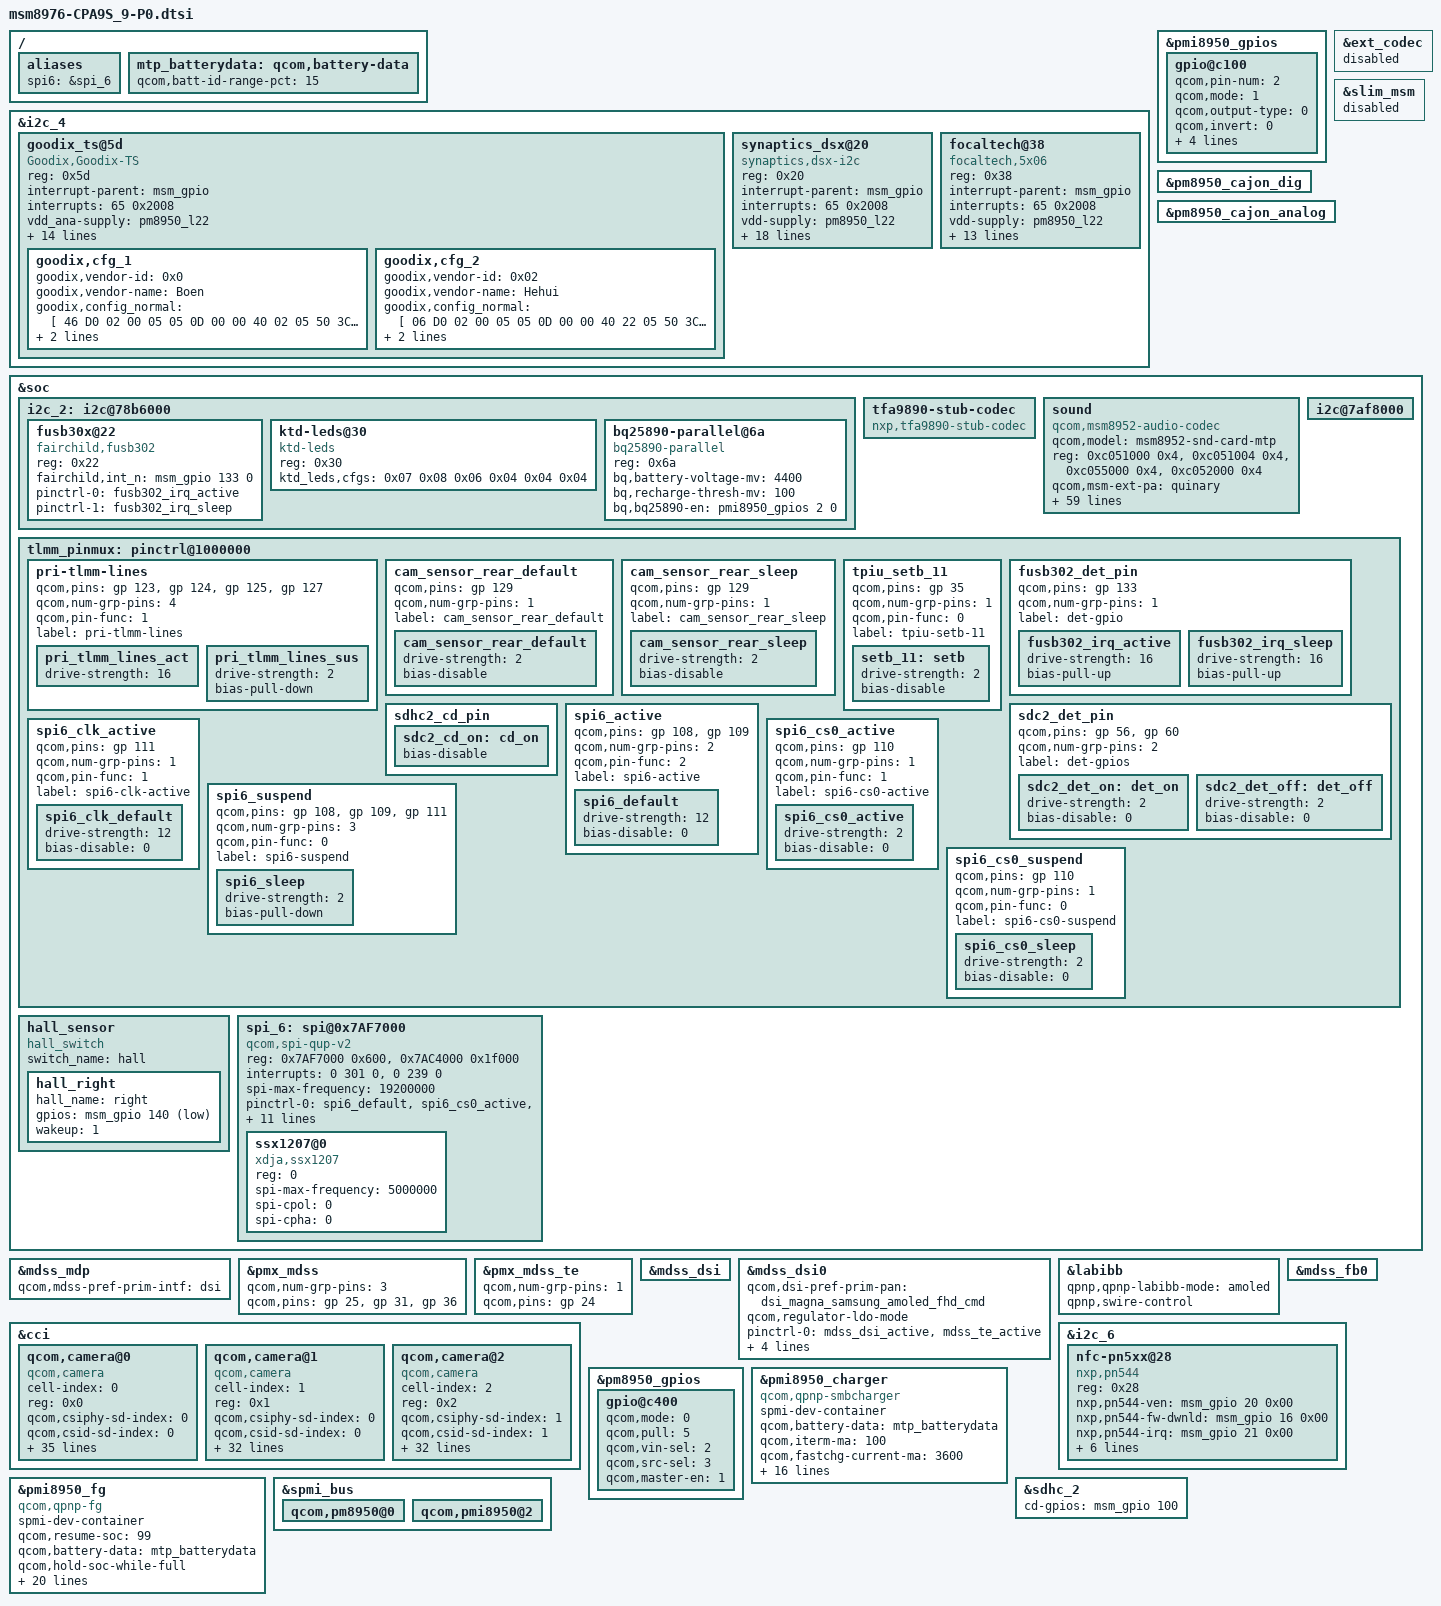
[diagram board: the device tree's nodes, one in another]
/* Copyright (c) 2014, The Linux Foundation. All rights reserved.
 *
 * This program is free software; you can redistribute it and/or modify
 * it under the terms of the GNU General Public License version 2 and
 * only version 2 as published by the Free Software Foundation.
 *
 * This program is distributed in the hope that it will be useful,
 * but WITHOUT ANY WARRANTY; without even the implied warranty of
 * MERCHANTABILITY or FITNESS FOR A PARTICULAR PURPOSE.  See the
 * GNU General Public License for more details.
 */

/* project CPA9S_9 */
/ {
	aliases {

		spi6 = &spi_6;
	};

};




&i2c_4 {
                goodix_ts@5d {
                        compatible = "Goodix,Goodix-TS";
                        reg = <0x5d>;
                        interrupt-parent = <&msm_gpio>;  /*<&tlmm>;*/
                        interrupts = <65 0x2008>;
                        vdd_ana-supply = <&pm8950_l22>;
                        vcc_i2c-supply = <&pm8950_l6>;
                        /* pins used by touchscreen */
                        pinctrl-names = "pmx_ts_active","pmx_ts_suspend";
                        pinctrl-0 = <&ts_int_active &ts_reset_active>;
                        pinctrl-1 = <&ts_int_suspend &ts_reset_suspend>;
                        goodix,vcc_i2c_supply_en = <&msm_gpio 35 0x0>;
                        goodix,irq-gpio = <&msm_gpio 65 0x2008>;	/*<&tlmm 65 0x2008> ;*/
                        goodix,reset-gpio = <&msm_gpio 64 0x0>; /*<&tlmm 64 0x0>;*/
                        goodix,irq_flags = <0x2>;
                        goodix,pixel = <720 1280>;
                        goodix,pwr_ctrl = <1>;
                        goodix,vdd = "vdd_ana";
                        goodix,vddio = "vcc_i2c";
                        goodix,ic_type = "GT1151";
                        goodix,charger_status_force_check = <0>;
                        goodix,cover = <0 0 540 300>; //x_min, y_min, x_max, y_max
                        /*touch config file*/

                        goodix,cfg_1 {
                                goodix,vendor-id = <0x0>;
                                goodix,vendor-name = "Boen";
                                goodix,config_normal = [
                                        46 D0 02 00 05 05 0D 00 00 40 02 05 50 3C 73 01 11
                                        00 00 00 41 8C A0 BE 08 00 00 00 00 00 00 00 00 31
                                        00 00 00 14 00 00 00 00 00 00 00 00 88 28 1C 52 54
                                        DF 07 38 6E 38 0D 33 24 00 04 32 78 C0 94 02 1E 0B
                                        03 C8 3D A6 49 8F 54 80 60 73 6C 6A 00 00 00 00 00
                                        00 00 00 00 00 00 00 00 19 19 00 00 00 00 00 0C 00
                                        00 00 00 00 88 00 00 00 00 00 FF 80 04 00 00 00 00
                                        00 00 00 00 00 00 00 00 00 00 00 00 00 00 00 00 00
                                        D0 07 41 1E 1F 1E 1D 1C 1B 1A 19 18 17 16 15 14 13
                                        0F 10 0E 0D 0C 0A 0B 09 08 06 07 04 05 02 03 FF FF
                                        FF 00 10 0F 0E 0D 0C 0B 0A 09 08 07 06 05 02 04 03
                                        01 FF 00 00 00 00 00 00 00 00 00 13 00 00 00 00 00
                                        00 00 00 00 00 00 00 00 00 00 00 00 00 00 00 00 00
                                        00 23 54 6E 31 14 3C 00 3A 20 03 00 D0 07 54 94 C7
                                        01
                                ];
                                goodix,config_glove = [
                                        46 D0 02 00 05 05 0D 00 00 40 02 05 46 32 73 01 11
                                        00 00 00 50 8C A0 BE 08 00 00 00 00 00 00 00 00 31
                                        00 00 00 14 00 00 00 00 00 00 00 00 88 28 1C 54 56
                                        DF 07 38 6E 38 0E 34 24 00 04 32 78 C0 94 02 1E 0B
                                        03 CD 3D A9 49 90 54 7F 60 72 6C 68 00 00 00 00 00
                                        00 00 00 00 00 00 00 00 19 19 00 00 00 00 00 0C 00
                                        00 00 00 00 88 00 00 00 00 00 FF 80 04 04 0A 0F 03
                                        1E B0 E1 E1 38 00 00 00 00 00 00 00 00 00 00 00 00
                                        D0 07 41 1E 1F 1E 1D 1C 1B 1A 19 18 17 16 15 14 13
                                        0F 10 0E 0D 0C 0A 0B 09 08 06 07 04 05 02 03 FF FF
                                        FF 00 10 0F 0E 0D 0C 0B 0A 09 08 07 06 05 02 04 03
                                        01 FF 00 00 00 00 00 00 00 00 00 13 00 00 00 00 00
                                        00 00 00 00 00 00 00 00 00 00 00 00 00 00 00 00 00
                                        00 23 54 6E 31 14 3C 00 3A 20 03 00 D0 07 54 94 C7
                                        01
                                ];
                        };
                         goodix,cfg_2 {
                                goodix,vendor-id = <0x02>;
                                goodix,vendor-name = "Hehui";
                                goodix,config_normal = [
					06 D0 02 00 05 05 0D 00 00 40 22 05 50 3C 73 01 11
					00 00 00 41 8C A0 BE 08 00 05 0A 00 00 00 11 00 31
					00 00 00 14 00 50 00 00 00 00 00 00 88 08 1C 49 00
					DF 07 38 6E 38 0D 33 24 11 04 32 78 C0 94 02 1E 0C
					03 C6 3D A5 49 8E 54 7F 60 73 6C 6B 00 00 00 00 00
					00 00 00 00 00 00 00 00 19 19 00 00 00 00 00 0C 00
					00 00 00 00 88 00 00 00 00 00 FF 80 04 00 00 00 00
					00 00 00 00 00 00 00 00 00 00 00 00 00 00 00 00 00
					C5 04 41 23 1F 1E 1D 1C 1B 1A 19 18 17 16 15 14 13
					12 10 0F 0E 0D 0C 0B 0A 09 08 07 06 05 04 03 FF FF
					FF 00 10 0F 0E 0D 0C 0B 0A 09 08 07 06 05 04 03 02
					01 FF 00 00 00 00 00 00 00 00 00 13 00 00 00 00 00
					00 00 00 00 00 00 00 00 00 00 00 00 00 00 00 00 00
					00 13 49 6D 31 14 3C 00 35 20 00 00 DF 07 49 14 7C
					01
                                ];
                                 goodix,config_glove = [
			                    08 D0 02 00 05 05 0D 00 00 40
			                    22 05 46 32 73 01 11 00 00 01
			                    3C 80 A0 CA 08 00 05 0A 00 00
			                    00 11 00 31 00 00 00 14 00 50
			                    00 00 00 00 00 00 88 28 1C 49
			                    4B DF 07 38 6D 38 0E 34 24 11
			                    04 32 78 C0 94 02 1E 14 04 B9
			                    3D 9E 49 8B 54 8B 60 77 6C 71
			                    00 00 00 00 00 00 00 00 00 00
			                    00 00 00 19 19 00 00 00 00 00
			                    0C 00 00 00 00 00 88 00 00 00
			                    00 00 FF 80 04 05 0A 0F 03 1E
			                    78 AA E1 38 00 00 00 00 00 00
			                    00 00 00 00 00 00 C5 04 3C 23
			                    03 05 04 07 06 09 08 0B 0A 0C
			                    0E 0D 0F 10 12 14 16 18 1A 1C
			                    1E 13 15 17 19 1B 1F 1D FF FF
			                    FF 00 01 03 02 05 04 06 07 09
			                    08 0B 10 0A 0F 0C 0E 0D FF 00
			                    00 00 00 00 00 00 00 00 13 00
			                    00 00 00 00 00 00 00 00 00 00
			                    00 00 00 00 00 00 00 00 00 00
			                    00 00 13 49 6D 31 14 3C 00 35
			                    20 03 00 D0 07 54 84 39 01
                                ];
                        };
                };

		/delete-node/ synaptics@20; 
             synaptics_dsx@20 {
			            compatible = "synaptics,dsx-i2c";
			            reg = <0x20>;
			            interrupt-parent = <&msm_gpio>;
			            interrupts = <65 0x2008>;
			            vdd-supply = <&pm8950_l22>;
			            vcc_i2c-supply = <&pm8950_l6>;
                                    synaptics,power-gpio = <&msm_gpio 35 0x0>;
                        	    synaptics,pwr-reg-name = "vdd";
                        	    synaptics,bus-reg-name = "vcc_i2c";
			            pinctrl-names = "pmx_ts_active","pmx_ts_suspend","pmx_ts_suspend";
			            pinctrl-0 = <&ts_int_active &ts_reset_active>;
			            pinctrl-1 = <&ts_int_suspend &ts_reset_suspend>;
                        	    pinctrl-2 = <&ts_release>;
			            synaptics,irq-gpio = <&msm_gpio 65 0x2008>;
			            synaptics,reset-gpio = <&msm_gpio 64 0x0>;
                        	    synaptics,irq-flags = <0x2008>;  
			            synaptics,power-delay-ms = <200>;
                                    synaptics,power-on-state = <1>;
			            synaptics,reset-delay-ms = <200>;
			            synaptics,reset-on-state = <0>;
			            synaptics,reset-active-ms = <20>;
                        	    synaptics,cap-button-codes = <580 102 158>;
                                    synaptics,x-flip = <1>;
                                    synaptics,y-flip = <1>;
		            };

    		focaltech@38{
			compatible = "focaltech,5x06";
			reg = <0x38>;
			interrupt-parent = <&msm_gpio>;
			interrupts = <65 0x2008>;
			vdd-supply = <&pm8950_l22>;
			vcc_i2c-supply = <&pm8950_l6>;
        	        focaltech,vcc_i2c_supply_en = <&msm_gpio 35 0x0>;
			focaltech,family-id = <0x06>;
			focaltech,reset-gpio = <&msm_gpio 64 0x0>;
			focaltech,irq-gpio = <&msm_gpio 65 0x2008>;
			focaltech,irq_flags = <0x2008>;
			focaltech,screen_x = <1080>;
			focaltech,screen_y = <1920>;
			focaltech,display-coords = <0 0 1080 1920>;
			focaltech,panel-coords = <0 0 1080 1920>;
			focaltech,button-map= <139 102 158>;
			focaltech,no-force-update;
			focaltech,i2c-pull-up;
		};

         /* shtsc tw */
/*	shtsc@18 {
		compatible = "sharp,shtsc_i2c";	
		reg = <0x18>;
		interrupt-parent = <&msm_gpio>;
		interrupts = <65 0x2008>;// high-level trigger. but hard coded in the source.
		vdd-supply = <&pm8950_l10>;
		vcc_i2c-supply = <&pm8950_l6>;
		sharp,vcc-i2c-supply-en = <&msm_gpio 34 0x00>;
		sharp,reset-gpio = <&msm_gpio 64 0x00>;
		sharp,irq-gpio = <&msm_gpio 65 0x2008>;
		pinctrl-names = "pmx_ts_active","pmx_ts_suspend";
		pinctrl-0 = <&ts_int_active &ts_reset_active>;
		pinctrl-1 = <&ts_int_suspend &ts_reset_suspend>;
		sharp,panel-coords = <0 0 1079 1919>; // depends on an LCD resolution (0 0 Xmax-1 Ymax-1)
		sharp,display-coords = <0 0 1079 1919>; // depends on an LCD resolution (0 0 Xmax-1 Ymax-1)
		sharp,i2c-pull-up;
		ts_touch_num_max = <10>;
		ts_pressure_max = <65535>;
		ts_flip_x = <0>;
		ts_flip_y = <0>;
		ts_swap_xy = <0>;

	};*/
};

&i2c_2 {
       /*KTD2026 Led*/
        ktd-leds@30 {
               compatible = "ktd-leds";
                reg = <0x30>;
                ktd_leds,cfgs = <
                    0x07 /*ktd_red_out Register */
                    0x08 /*ktd_green_out Register*/
                    0x06 /*ktd_blue_out Register */

                    0x04 /*ktd_red_current,15mA */
                    0x04 /*ktd_green_current,15mA */
                    0x04 /*ktd_blue_current,15mA */
                    >;
                };
                /*add end*/

	bq25890-parallel@6a {
                     compatible = "bq25890-parallel";
                     reg = <0x6a>;
                     bq,battery-voltage-mv = <4400>;
                     bq,recharge-thresh-mv = <100>;
                     bq,bq25890-en = <&pmi8950_gpios 2 0>;
                  };
};

&pmi8950_gpios {
                gpio@c100 {
                     qcom,pin-num = <2>;
                     qcom,mode = <1>;
                     qcom,output-type = <0>;
                     qcom,invert = <0>;
                     qcom,pull = <5>;
                     qcom,vin-sel = <0>;
                     qcom,src-sel = <2>;
                     qcom,master-en = <1>;
                     status = "okay";
               };
};

/**audio:disable external codec and enable internal codec,by lijiakan--start*/
&ext_codec {
        status = "disabled";
};
&slim_msm{
        status = "disabled";
};

&pm8950_cajon_dig {
        status = "ok";
};

&pm8950_cajon_analog {
        status = "ok";
};

&slim_msm {
	/delete-node/ tasha_codec;
};
&tlmm_pinmux {

                /delete-node/ cam_sensor_rear_default;
                cam_sensor_rear_default {
                        /* RESET, STANDBY */
                        qcom,pins = <&gp 129> ;
                        qcom,num-grp-pins = <1>;
                        label = "cam_sensor_rear_default";
                        /* active state */
                        cam_sensor_rear_default: cam_sensor_rear_default {
                                drive-strength = <2>; /* 2 MA */
                                bias-disable; /* No PULL */
                        };
                };

                /delete-node/ cam_sensor_rear_sleep;
                cam_sensor_rear_sleep {
                        /* RESET, STANDBY */
                        qcom,pins = <&gp 129>;
                        qcom,num-grp-pins = <1>;
                        label = "cam_sensor_rear_sleep";
                        /*suspended state */
                        cam_sensor_rear_sleep: cam_sensor_rear_sleep {
                                drive-strength = <2>; /* 2 MA */
                                bias-disable; /* No PULL */
                        };
                };

                tpiu_setb_11 {
                        qcom,pins = <&gp 35>;
                        qcom,num-grp-pins = <1>;
                        qcom,pin-func = <0>;
                        label = "tpiu-setb-11";
                        setb_11: setb {
                                drive-strength = <2>;
                                bias-disable;
                        };
                };

	fusb302_det_pin {
		qcom,pins = <&gp 133>;
		qcom,num-grp-pins = <1>;
		label = "det-gpio";
		fusb302_irq_active: fusb302_irq_active {
			drive-strength = <16>;
			bias-pull-up;
		};
		fusb302_irq_sleep: fusb302_irq_sleep {
			drive-strength = <16>;
			bias-pull-up;
		};
	};
};

/**audio:disable external codec and enable internal codec,by lijiakan  --end*/
/* fengdongjie add dts for audio start */
&soc {


	i2c_2: i2c@78b6000 { /* BLSP1 QUP2 */
		/* add usb type c for fusb302 */
		fusb30x@22 {
			compatible = "fairchild,fusb302";
                        reg = <0x22>;
                        fairchild,int_n = <&msm_gpio 133 0>;
                        pinctrl-names = "default", "sleep";
                        pinctrl-0 = <&fusb302_irq_active>;
                        pinctrl-1 = <&fusb302_irq_sleep>;
		};
	};

        /* add by wangyanzhong for tfa9890 */
        tfa9890-stub-codec {
                compatible = "nxp,tfa9890-stub-codec";
        };
        /* add end for tfa9890*/

	/delete-node/ sound-9335;
        sound {
                compatible = "qcom,msm8952-audio-codec";
                qcom,model = "msm8952-snd-card-mtp";
                reg = <0xc051000 0x4>,
                    <0xc051004 0x4>,
                    <0xc055000 0x4>,
                    <0xc052000 0x4>;
                reg-names = "csr_gp_io_mux_mic_ctl",
                        "csr_gp_io_mux_spkr_ctl",
                        "csr_gp_io_lpaif_pri_pcm_pri_mode_muxsel",
                        "csr_gp_io_mux_quin_ctl";

                /delete-property/ qcom,msm-ext-pa;
                qcom,msm-ext-pa = "quinary";
                qcom,msm-mclk-freq = <9600000>;
                qcom,msm-mbhc-hphl-swh = <1>;
                qcom,msm-mbhc-gnd-swh = <1>;
                qcom,msm-hs-micbias-type = "external";
                qcom,msm-micbias1-ext-cap;
                /* qcom,msm-spk-boost-ctl = <&msm_gpio 132 0>;*/
                qcom,audio-routing =
                        "RX_BIAS", "MCLK",
                        "SPK_RX_BIAS", "MCLK",
                        "INT_LDO_H", "MCLK",
                        "MIC BIAS External", "Handset Mic",
                        "MIC BIAS External2", "Headset Mic",
                        "MIC BIAS External", "Secondary Mic",
                        "AMIC1", "MIC BIAS External",
                        "AMIC2", "MIC BIAS External2",
                        "AMIC3", "MIC BIAS External";
                qcom,msm-gpios =
                        "pri_i2s",
                        /*"us_eu_gpio";*/
			"quin_i2s";
                qcom,pinctrl-names =
                        "all_off",
                        "pri_i2s_act",
                        /*"us_eu_gpio_act",
                         "pri_i2s_us_eu_gpio_act";*/
			"quin_i2s_act",
			"pri_i2s_quin_i2s_act";
                pinctrl-names =
                        "all_off",
                        "pri_i2s_act",
                        /*"us_eu_gpio_act",
                          "pri_i2s_us_eu_gpio_act";*/
			"quin_i2s_act",
			"pri_i2s_quin_i2s_act";
                /delete-property/ pinctrl-0;
                /delete-property/ pinctrl-1;
                /delete-property/ pinctrl-2;
                /delete-property/ pinctrl-3;

                pinctrl-0 = <&cdc_pdm_lines_sus &cdc_pdm_lines_2_sus &pri_tlmm_lines_sus>;
                pinctrl-1 = <&cdc_pdm_lines_act &cdc_pdm_lines_2_act &pri_tlmm_lines_sus>;
		pinctrl-2 = <&cdc_pdm_lines_sus &cdc_pdm_lines_2_sus &pri_tlmm_lines_act>;
		pinctrl-3 = <&cdc_pdm_lines_act &cdc_pdm_lines_2_act &pri_tlmm_lines_act>;

                /delete-property/ qcom,cdc-us-euro-gpios;
                asoc-platform = <&pcm0>, <&pcm1>, <&pcm2>, <&voip>, <&voice>,
                        <&loopback>, <&compress>, <&hostless>,
                        <&afe>, <&lsm>, <&routing>, <&lpa>,
                        <&voice_svc>;
                asoc-platform-names = "msm-pcm-dsp.0", "msm-pcm-dsp.1", "msm-pcm-dsp.2",
                        "msm-voip-dsp", "msm-pcm-voice", "msm-pcm-loopback",
                        "msm-compress-dsp", "msm-pcm-hostless", "msm-pcm-afe",
                        "msm-lsm-client", "msm-pcm-routing", "msm-pcm-lpa",
                        "msm-voice-svc";
                asoc-cpu = <&dai_pri_auxpcm>, <&dai_hdmi>,
                        <&dai_mi2s0>, <&dai_mi2s1>, <&dai_mi2s2>, <&dai_mi2s3>,
                        <&dai_mi2s5>,<&dai_mi2s6>,
                        <&sb_0_rx>, <&sb_0_tx>, <&sb_1_rx>, <&sb_1_tx>,
                        <&sb_3_rx>, <&sb_3_tx>, <&sb_4_rx>, <&sb_4_tx>,
                        <&bt_sco_rx>, <&bt_sco_tx>, <&int_fm_rx>, <&int_fm_tx>,
                        <&afe_pcm_rx>, <&afe_pcm_tx>, <&afe_proxy_rx>, <&afe_proxy_tx>,
                        <&incall_record_rx>, <&incall_record_tx>, <&incall_music_rx>,
                        <&incall_music_2_rx>;
                asoc-cpu-names = "msm-dai-q6-auxpcm.1", "msm-dai-q6-hdmi.8",
                        "msm-dai-q6-mi2s.0", "msm-dai-q6-mi2s.1",
                        "msm-dai-q6-mi2s.2", "msm-dai-q6-mi2s.3",
                        "msm-dai-q6-mi2s.5","msm-dai-q6-mi2s.6",
                        "msm-dai-q6-dev.16384", "msm-dai-q6-dev.16385",
                        "msm-dai-q6-dev.16386", "msm-dai-q6-dev.16387",
                        "msm-dai-q6-dev.16390", "msm-dai-q6-dev.16391",
                        "msm-dai-q6-dev.16392", "msm-dai-q6-dev.16393",
                        "msm-dai-q6-dev.12288", "msm-dai-q6-dev.12289",
                        "msm-dai-q6-dev.12292", "msm-dai-q6-dev.12293",
                        "msm-dai-q6-dev.224", "msm-dai-q6-dev.225",
                        "msm-dai-q6-dev.241", "msm-dai-q6-dev.240",
                        "msm-dai-q6-dev.32771", "msm-dai-q6-dev.32772",
                        "msm-dai-q6-dev.32773", "msm-dai-q6-dev.32770";
                asoc-codec = <&stub_codec>, <&pm8950_cajon_dig>;
                asoc-codec-names = "msm-stub-codec.1", "cajon_codec";
                /delete-property/ asoc-wsa-codec-names;
                /delete-property/ asoc-wsa-codec-prefixes;
                /delete-property/ msm-vdd-wsa-switch-supply;
                /delete-property/ qcom,msm-vdd-wsa-switch-voltage;
                /delete-property/ qcom,msm-vdd-wsa-switch-current;
        };
        i2c@7af8000 {
                /delete-node/ wsa881x-i2c-codec@e;
                /delete-node/ wsa881x-i2c-codec@44;
                /delete-node/ wsa881x-i2c-codec@f;
                /delete-node/ wsa881x-i2c-codec@45;
        };
	tlmm_pinmux: pinctrl@1000000 {
		/delete-node/ pri-tlmm-lines;
		pri-tlmm-lines {
			qcom,pins = <&gp 123>, <&gp 124>, <&gp 125>,<&gp 127>;
			qcom,num-grp-pins = <4>;
			qcom,pin-func = <1>;
			label = "pri-tlmm-lines";
			pri_tlmm_lines_act: pri_tlmm_lines_act {
				drive-strength = <16>;
				};
			pri_tlmm_lines_sus:  pri_tlmm_lines_sus {
				drive-strength = <2>;
				bias-pull-down;
				};
			};
	};
	

};
/* fengdongjie add dts for audio end */

/*added by lvle for display begin*/
#include "yulong-dsi-panel-sh1387-hehui-amoled-hd-500-video.dtsi"
#include "yulong-dsi-panel-magna-samsung-amoled-fhd-550-cmd.dtsi"

&mdss_mdp {
	qcom,mdss-pref-prim-intf = "dsi";
};

&pmx_mdss {
	qcom,num-grp-pins = <3>;
	qcom,pins = <&gp 25>, <&gp 31>, <&gp 36>;
};

&pmx_mdss_te {
	qcom,num-grp-pins = <1>;
	qcom,pins = <&gp 24>;
};

&mdss_dsi {
	/delete-node/ qcom,mdss_dsi_ctrl1@1a96000;
};

&mdss_dsi0 {
	/delete-property/ vdd-supply;
	/delete-property/ vddio-supply;
	qcom,dsi-pref-prim-pan = <&dsi_magna_samsung_amoled_fhd_cmd>;
	qcom,regulator-ldo-mode;

	pinctrl-names = "mdss_default", "mdss_sleep";
	pinctrl-0 = <&mdss_dsi_active &mdss_te_active>;
	pinctrl-1 = <&mdss_dsi_suspend &mdss_te_suspend>;

	qcom,platform-reset-gpio = <&msm_gpio 25 0>;
	qcom,platform-vddi-enable-gpio = <&msm_gpio 31 0>;
	qcom,platform-vci-enable-gpio = <&msm_gpio 36 0>;
};

&labibb {
	status = "ok";
	qpnp,qpnp-labibb-mode = "amoled";
	qpnp,swire-control;
};

&mdss_fb0 {
	/delete-property/ qcom,mdss-fb-splash-logo-enabled;
	/delete-node/ qcom,cont-splash-memory;
};
/*added by lvle for display end*/

&cci {
	/delete-node/ qcom,actuator@0;
	/delete-node/ qcom,actuator@1;
	/delete-node/ qcom,camera@0;
	/delete-node/ qcom,camera@1;
	/delete-node/ qcom,camera@2;
	/delete-node/ qcom,camera@78;
	/delete-node/ qcom,eeprom@0;
	/delete-node/ qcom,eeprom@1;
	/delete-node/ qcom,eeprom@2;

/*
	actuator0: qcom,actuator@0 {
		cell-index = <0>;
		reg = <0x0>;
		compatible = "qcom,actuator";
		qcom,cci-master = <0>;
		cam_vaf-supply = <&pm8950_l17>; //cn:
		qcom,cam-vreg-name = "cam_vaf";
		qcom,cam-vreg-min-voltage = <2850000>;
		qcom,cam-vreg-max-voltage = <2850000>;
		qcom,cam-vreg-op-mode = <100000>;
	};
*/



	qcom,camera@0 {
		cell-index = <0>;
		compatible = "qcom,camera";
		reg = <0x0>;
		qcom,csiphy-sd-index = <0>;
		qcom,csid-sd-index = <0>;
		qcom,mount-angle = <90>;
	//	qcom,eeprom-src = <&eeprom0>;
	//	qcom,actuator-src = <&actuator0>;
//		qcom,led-flash-src = <&led_flash0>;
		cam_vdig-supply = <&pm8950_l3>;	//DVDD	1.2 must change to 1.05V !!!
		cam_vio-supply = <&pm8950_l6>;		//no use DOVDD	1.8
		cam_vana-supply = <&pm8950_l6>;		//for place ,actually use GPIO
//		cam_vaf-supply = <&pm8950_l17>;		//VAAM	2.85
		qcom,cam-vreg-name = "cam_vdig", "cam_vio", "cam_vana";
		qcom,cam-vreg-min-voltage = <1050000 1800000 1800000 >;
		qcom,cam-vreg-max-voltage = <1050000 1800000 1800000 >;
		qcom,cam-vreg-op-mode = <200000 100000 100000 >;
		pinctrl-names = "cam_default", "cam_suspend";
		pinctrl-0 = <&cam_sensor_mclk0_default
				&cam_sensor_rear_default>;
		pinctrl-1 = <&cam_sensor_mclk0_sleep &cam_sensor_rear_sleep>;
		qcom,gpio-no-mux = <0>;
		gpios = <&msm_gpio 26 0>,	//CAM_MCLK0
			<&msm_gpio 129 0>,		//CAM0_RST
			<&msm_gpio 63 0>,		//MCAM_AVDD_EN
			<&msm_gpio 32 0>,		//MCAM_DOVDD_EN
			<&msm_gpio 33 0>,		//MCAM_DVDD_EN
			<&msm_gpio 18 0>; //mipi 0 8m 1 12m

		qcom,gpio-reset = <1>;
		qcom,gpio-vana = <2>;
		qcom,gpio-vio = <3>;
		qcom,gpio-vdig = <4>;
        qcom,gpio-standby = <5>;
		qcom,gpio-req-tbl-num = <0 1 2 3 4 5>;
		qcom,gpio-req-tbl-flags = <1 0 0 0 0 0>;

		qcom,gpio-req-tbl-label = "CAMIF_MCLK0",
			"CAM_RESET0",
			"CAM_VANA0",
			"CAM_VIO0",
			"CAM_DVDD0",
			"CAM_MIPI12M";

		qcom,csi-lane-assign = <0x4320>;
		qcom,csi-lane-mask = <0x1f>;
		qcom,sensor-position = <0>;
		qcom,sensor-mode = <0>;
		qcom,cci-master = <1>;
		status = "ok";
		clocks = <&clock_gcc clk_mclk0_clk_src>,
			     <&clock_gcc clk_gcc_camss_mclk0_clk>;
		clock-names = "cam_src_clk", "cam_clk";
	};


	//OV8865
	qcom,camera@1 {
		cell-index = <1>;
		compatible = "qcom,camera";
		reg = <0x1>;
		qcom,csiphy-sd-index = <0>;
		qcom,csid-sd-index = <0>;
		qcom,mount-angle = <270>;

		cam_vio-supply = <&pm8950_l6>;		//no use DOVDD	1.8
		cam_vana-supply = <&pm8950_l22>;	//no use AVDD 2.85
        cam_vdig-supply = <&pm8950_l23>;	//DVDD	1.2 must change to 1.05V !!!
		qcom,cam-vreg-name = "cam_vio", "cam_vana","cam_vdig";
		qcom,cam-vreg-min-voltage = <1800000 2800000 1200000>;
		qcom,cam-vreg-max-voltage = <1800000 2800000 1200000>;
		qcom,cam-vreg-op-mode = <105000 80000 100000>;
		qcom,gpio-no-mux = <0>;
		pinctrl-names = "cam_default", "cam_suspend";
		pinctrl-0 = <&cam_sensor_mclk1_default &cam_sensor_front1_default>;
		pinctrl-1 = <&cam_sensor_mclk1_sleep &cam_sensor_front1_sleep>;
		gpios = <&msm_gpio 27 0>,//MCLK1
            <&msm_gpio 130 0>, //RESET
			<&msm_gpio 32 0>, //dovdd
			<&msm_gpio 63 0>, //avdd
			<&msm_gpio 18 0>; //mipi 0 8m 1 12m

		qcom,gpio-reset = <1>;
		qcom,gpio-vio = <2>;
		qcom,gpio-vana = <3>;
        qcom,gpio-standby = <4>;
		qcom,gpio-req-tbl-num = <0 1 2 3 4>;
		qcom,gpio-req-tbl-flags = <1 0 0 0 0>;
		qcom,gpio-req-tbl-label = "CAMIF_MCLK8M",
					  "CAM_RESET8M",
					  "CAM_VIO8M",
					  "CAM_AVDD8M",
					  "CAM_MIPI8M";
		qcom,sensor-position = <1>;
		qcom,sensor-mode = <0>;
		qcom,cci-master = <1>;
		status = "ok";
		clocks = <&clock_gcc clk_mclk1_clk_src>,
			<&clock_gcc clk_gcc_camss_mclk1_clk>;
		clock-names = "cam_src_clk", "cam_clk";
	};

	//OV5695
	qcom,camera@2 {
		cell-index = <2>;
		compatible = "qcom,camera";
		reg = <0x2>;
		qcom,csiphy-sd-index = <1>;
		qcom,csid-sd-index = <1>;
		qcom,mount-angle = <270>;

		cam_vio-supply = <&pm8950_l6>;		//no use DOVDD	1.8
		cam_vana-supply = <&pm8950_l22>;	//no use AVDD 2.85
        cam_vdig-supply = <&pm8950_l23>;	//DVDD	1.2 must change to 1.05V !!!
		qcom,cam-vreg-name = "cam_vio", "cam_vana","cam_vdig";
		qcom,cam-vreg-min-voltage = <1800000 2800000 1200000>;
		qcom,cam-vreg-max-voltage = <1800000 2800000 1200000>;
		qcom,cam-vreg-op-mode = <105000 80000 100000>;
		qcom,gpio-no-mux = <0>;
		pinctrl-names = "cam_default", "cam_suspend";
		pinctrl-0 = <&cam_sensor_mclk2_default &cam_sensor_front1_default>;
		pinctrl-1 = <&cam_sensor_mclk2_sleep &cam_sensor_front1_sleep>;
		gpios = <&msm_gpio 28 0>,//MCLK2
            <&msm_gpio 131 0>, //RESET
			<&msm_gpio 105 0>, //dovdd
			<&msm_gpio 69 0>, //avdd
			<&msm_gpio 107 0>; //dvdd

		qcom,gpio-reset = <1>;
		qcom,gpio-vio = <2>;
		qcom,gpio-vana = <3>;
		qcom,gpio-vdig = <4>;
		qcom,gpio-req-tbl-num = <0 1 2 3 4>;
		qcom,gpio-req-tbl-flags = <1 0 0 0 0>;
		qcom,gpio-req-tbl-label = "CAMIF_MCLK5M",
					  "CAM_RESET5M",
					  "CAM_VIO5M",
					  "CAM_AVDD5M",
					  "CAM_DVDD5M";
		qcom,sensor-position = <1>;
		qcom,sensor-mode = <0>;
		qcom,cci-master = <0>;
		status = "ok";
		clocks = <&clock_gcc clk_mclk2_clk_src>,
			<&clock_gcc clk_gcc_camss_mclk2_clk>;
		clock-names = "cam_src_clk", "cam_clk";
	};

};
/* Added by chenshuanglong for hall sensor 2016/03/2 */
&soc {
    hall_sensor {
        compatible = "hall_switch";
        switch_name = "hall";
        hall_right {
            hall_name = "right";
            gpios = <&msm_gpio 140 0x1>;
            wakeup = <1>;
        };
    };
};
/* end added by chenshuanglong for hall sensor 2016/03/2 */

/* Add start by Lynn 2016/02/17 */
/* Add NXP NFC essential configurations */
/* Delete NQ node to avoid conflict */
&i2c_6 {
    /delete-node/ nq@2b;
};
&soc {
    /delete-node/ qcom,cnss_sdio;
    /delete-node/ rome_vreg;
    /delete-node/ bt_vreg;
};

/* Add CLK_REQ config for NQ220 */
&pm8950_gpios {
    gpio@c400 { /* GPIO 5 */
        /delete-property/ status;
        /* NFC_CLK_REQ */
        qcom,mode = <0>; /* QPNP_PIN_MODE_DIG_IN */
        qcom,pull = <5>; /* QPNP_PIN_PULL_NO */
        qcom,vin-sel = <2>; /* QPNP_PIN_VIN2 */
        qcom,src-sel = <3>; /* QPNP_PIN_SEL_FUNC_2 */
        qcom,master-en = <1>;
    };
};

/* Add NQ220 Chip configuration */
&i2c_6 { /* BLSP6*/
    nfc-pn5xx@28 {
        compatible = "nxp,pn544";
        reg = <0x28>;
        nxp,pn544-ven = <&msm_gpio 20 0x00>;
        nxp,pn544-fw-dwnld = <&msm_gpio 16 0x00>;
        nxp,pn544-irq = <&msm_gpio 21 0x00>;
        nxp,pn544-ese-pwr = <&msm_gpio 34 0x00>; /* use random pin-num */
        nxp,pn5xx-clkreq = <&pm8950_gpios 5 0x00>;
        nxp,clk-src = "BBCLK2";
        clocks = <&clock_gcc clk_bb_clk2_pin>;
        clock-names = "ref_clk";
        interrupt-parent = <&msm_gpio>;
        interrupts = <21 0>;
        interrupt-names = "nfc_irq";
    };
};
/* Added end by Lynn 2016/02/17 */

/* add by laijiacheng 20160303 */
&pmi8950_charger{
           spmi-dev-container;
           compatible = "qcom,qpnp-smbcharger";
           #address-cells = <1>;
           #size-cells = <1>;

           qcom,battery-data = <&mtp_batterydata>;
           qcom,iterm-ma = <100>;
           qcom,fastchg-current-ma = <3600>;//100mA more
           qcom,float-voltage-mv = <4400>;
           qcom,resume-delta-mv = <50>;
           /delete-property/ qcom,chg-led-support;
           /delete-property/ qcom,chg-led-sw-controls;
           qcom,chg-inhibit-fg;
           qcom,dc-psy-type = "Mains";
           qcom,dc-psy-ma = <1500>;
           qcom,rparasitic-uohm = <100000>;
           qcom,bms-psy-name = "bms";
           qcom,thermal-mitigation = <2100 1800 1500 1200 900 600 0>;
           qcom,parallel-usb-min-current-ma = <1500>;
           qcom,parallel-usb-9v-min-current-ma = <1000>;
           qcom,parallel-allowed-lowering-ma = <600>;
           qcom,autoadjust-vfloat;
           qcom,smbchg-adc_tm = <&pm8950_adc_tm>;
           qcom,smbchg-vadc = <&pm8950_vadc>;
          qcom,dcin-vadc = <&pmi8950_vadc>;
           /delete-property/ qcom,charge-unknown-battery;
   };

&pmi8950_fg{
          spmi-dev-container;
          compatible = "qcom,qpnp-fg";
          #address-cells = <1>;
          #size-cells = <1>;
          qcom,resume-soc = <99>;
          qcom,battery-data = <&mtp_batterydata>;
          qcom,hold-soc-while-full;
          qcom,bad-battery-detection-enable;
          status = "okay";
          qcom,bcl-lm-threshold-ma = <127>;
          qcom,bcl-mh-threshold-ma = <405>;
          qcom,fg-cutoff-voltage-mv = <3350>;
          qcom,fg-iterm-ma = <500>;
          qcom,fg-chg-iterm-ma = <100>;
          qcom,cycle-counter-low-soc = <15>;
          qcom,cycle-counter-high-soc = <85>;
          qcom,ext-sense-type;
          qcom,cycle-counter-en;
          qcom,cycle-counter-low-soc = <15>;
          qcom,cycle-counter-high-soc = <85>;
          qcom,capacity-learning-on;
          qcom,fg-cc-cv-threshold-mv = <4390>;
          qcom,ext-sense-type;
          qcom,thermal-coefficients = <0xC2 0x86 0xBB 0x50 0xCF 0x37>;
          qcom,cold-bat-decidegc = <0>;
          qcom,hot-bat-decidegc = <500>;
          qcom,cool-bat-decidegc = <100>;
          qcom,warm-bat-decidegc = <400>;
          qcom,fg-vbatt-low-threshold = <3600>;
          qcom,fg-delta-soc = <2>;
  };

/* add batt data */
/{
mtp_batterydata: qcom,battery-data {
                         qcom,batt-id-range-pct = <15>;
#include "batterydata_CPAT366_100K.dtsi"
#include "batterydata_CPLD373_10K.dtsi"
#include "batterydata_CPTM366_1M.dtsi"
                 };
};

&spmi_bus {
         qcom,pm8950@0 {
                /delete-node/ qcom,leds@a300;
        };
	qcom,pmi8950@2{
		/delete-node/ qcom,leds@a100;
	};
};

/* add end*/

/*for SD card hotplug. frankie. 2016-03-04. start*/
&soc {
tlmm_pinmux: pinctrl@1000000 {
	sdhc2_cd_pin {
        	sdc2_cd_on: cd_on {
            		bias-disable;
            		};
    		};
	};
};
&tlmm_pinmux {
        /*configure sdcard gpio*/
        sdc2_det_pin {
                /* CS */
                qcom,pins = <&gp 56>,<&gp 60>;
                qcom,num-grp-pins = <2>;
                label = "det-gpios";
                sdc2_det_on: det_on  {
                        drive-strength = <2>;
                        bias-disable = <0>;
                };
                sdc2_det_off: det_off  {
                        drive-strength = <2>;
                        bias-disable = <0>;
                };
        };
};

&sdhc_2 {
	cd-gpios =  <&msm_gpio 100 0x0>; /*active high. frankie. 2016-03-04*/
};

/*for SD card hotplug. frankie. 2016-03-04. end*/

/*for xdja se. huangqingjun 2016-03-07.*/

&soc{
	spi_6: spi@0x7AF7000 { 
			compatible = "qcom,spi-qup-v2";
			reg-names = "spi_physical", "spi_bam_physical";
			reg = <0x7AF7000 0x600>,
					<0x7AC4000 0x1f000>;
			interrupt-names = "spi_irq", "spi_bam_irq";
			interrupts = <0 301 0>, <0 239 0>;
			spi-max-frequency = <19200000>;
			pinctrl-names = "spi_default", "spi_sleep";
			pinctrl-0 = <&spi6_default &spi6_cs0_active &spi6_clk_default>;
			pinctrl-1 = <&spi6_sleep &spi6_cs0_sleep>;
			clocks = <&clock_gcc clk_gcc_blsp2_ahb_clk>,
				 <&clock_gcc clk_gcc_blsp2_qup3_spi_apps_clk>;
			clock-names = "iface_clk", "core_clk";
			qcom,infinite-mode = <0>;
			qcom,use-bam;
			qcom,use-pinctrl;
			qcom,ver-reg-exists;
			qcom,bam-consumer-pipe-index = <8>;
			qcom,bam-producer-pipe-index = <9>;
			qcom,master-id = <84>;
			#address-cells = <1>;
			#size-cells = <0>;
			
			ssx1207@0 {
				compatible = "xdja,ssx1207";
				reg = <0>;
				spi-max-frequency = <5000000>;
				spi-cpol = <0>;
				spi-cpha = <0>;
			};
			
		};
	
	
	tlmm_pinmux: pinctrl@1000000{
		spi6_active {
			/* MOSI, MISO */
			qcom,pins = <&gp 108>, <&gp 109>;
			qcom,num-grp-pins = <2>;
			qcom,pin-func = <2>;
			label = "spi6-active";
			/* active state */
			spi6_default: spi6_default {
				drive-strength = <12>; /* 12 MA */
				bias-disable = <0>; /* No PULL */
			};
		};
		
		spi6_clk_active {
			/* CLK */
			qcom,pins = <&gp 111>;
			qcom,num-grp-pins = <1>;
			qcom,pin-func = <1>;
			label = "spi6-clk-active";
			/* active state */
			spi6_clk_default: spi6_clk_default {
				drive-strength = <12>; /* 12 MA */
				bias-disable = <0>; /* No PULL */
			};
		};

		spi6_suspend {
			/* MOSI, MISO, CLK */
			qcom,pins = <&gp 108>, <&gp 109>, <&gp 111>;
			qcom,num-grp-pins = <3>;
			qcom,pin-func = <0>;
			label = "spi6-suspend";
			/* suspended state */
			spi6_sleep: spi6_sleep {
				drive-strength = <2>; /* 2 MA */
				bias-pull-down; /* pull down */
			};
		};
		spi6_cs0_active {
			/* CS */
			qcom,pins = <&gp 110>;
			qcom,num-grp-pins = <1>;
			qcom,pin-func = <1>;
			label = "spi6-cs0-active";
			spi6_cs0_active: spi6_cs0_active {
				drive-strength = <2>;
				bias-disable = <0>;
			};
		};


		spi6_cs0_suspend {
			/* CS */
			qcom,pins = <&gp 110>;
			qcom,num-grp-pins = <1>;
			qcom,pin-func = <0>;
			label = "spi6-cs0-suspend";
			spi6_cs0_sleep: spi6_cs0_sleep {
				drive-strength = <2>;
				bias-disable = <0>;
				};
			};
		};
	};
	
/*for xdja se. huangqingjun 2016-03-07.end */
